# myChip register map
Vendor: ARM Ltd.; Series: ARMCM3; File version: 1.2
CPU: CM3 r2p1, little endian, no MPU, no FPU, 3 interrupt priority bits
Registers are 32-bit, read-write, reset 0x0 unless marked. A register's access mark holds for its fields unless they carry their own. Offsets are from the block's base; [hi:lo] are bit positions.

## WWDG
Base 0x4000D000
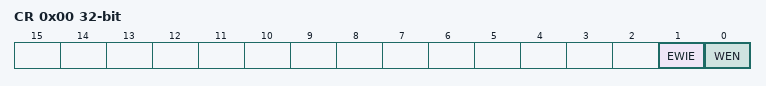
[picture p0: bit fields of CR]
0x00 CR — WWDG Control Register
  [1] EWIE — WWDG提前唤醒中断使能位（WWDG Early Wakeup Interrupt Enable）
  [0] WEN — WWDG使能位（WWDG Enable）
0x04 WVR — WWDG Window Register
  [15:0] WV — WWDG窗口比较值（WWDG Window Value）
0x08 CVR — WWDG Counter Register
  [15:0] CV — WWDG递减计数值（WWDG Counter Value）
0x0C PSCR — WWDG Prescaler Register
  [15:0] PSC — WWDG预分频器（WWDG Prescaler divider）
0x10 ISR — WWDG Status Register
  [0] EWIF — WWDG提前唤醒中断标志位（WWDG Early Wakeup Interrupt Flag）

## PDM0
Base 0x40017000
Same registers: PDM1 0x40017100, PDM2 0x40017200, PDM3 0x40017300
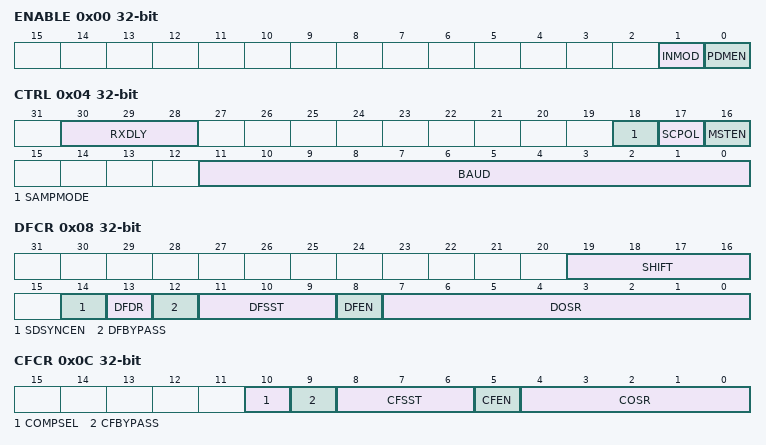
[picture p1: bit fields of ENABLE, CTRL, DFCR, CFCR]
0x00 ENABLE — PDM Enable Register
  [1] INMOD — PDM 输入模式位（PDM Input Mode）
  [0] PDMEN — PDM使能位（PDM Enable）
0x04 CTRL — PDM Control Register
  [30:28] RXDLY — SPI接收采样延迟（SPI RX Delay）
  [18] SAMPMODE — 从机时采样模式选择（Slave Sample Mode）
  [17] SCPOL — 串行时钟极性（Serial Clock Polarity）
  [16] MSTEN — PDM主机使能位（PDM Master Enable）
  [11:0] BAUD — 波特率配置（Baud Rate Configuration）
0x08 DFCR — PDM Main Filter Control Register
  [19:16] SHIFT — 移位控制选择位（Shift Control Select）
  [14] SDSYNCEN — SDSYNC信号使能位（SDSYNC Enable）
  [13] DFDR — 主滤波器输出数据位宽选择（Data Filter Output Data Length）
  [12] DFBYPASS — 主滤波器bypass使能（Data Filter Bypass Enable）
  [11:9] DFSST — 主滤波器类型（Data Filter Structure）
  [8] DFEN — 主滤波器使能位（Data Filter Enable）
  [7:0] DOSR — 主滤波器过采样值（Data filter Oversampling ratio）
0x0C CFCR — PDM Compare Filter Control Register
  [10] COMPSEL — 比较滤波器输出选择（Comparator Filter Output Select）
  [9] CFBYPASS — 比较滤波器bypass使能位（Comparator Filter Bypass Enable）
  [8:6] CFSST — 比较滤波器类型（Comparator Filter Structure）
  [5] CFEN — 比较滤波器使能位（Comparator Filter Enable）
  [4:0] COSR — 比较滤波器过采样值（Comparator filter Oversampling ratio）
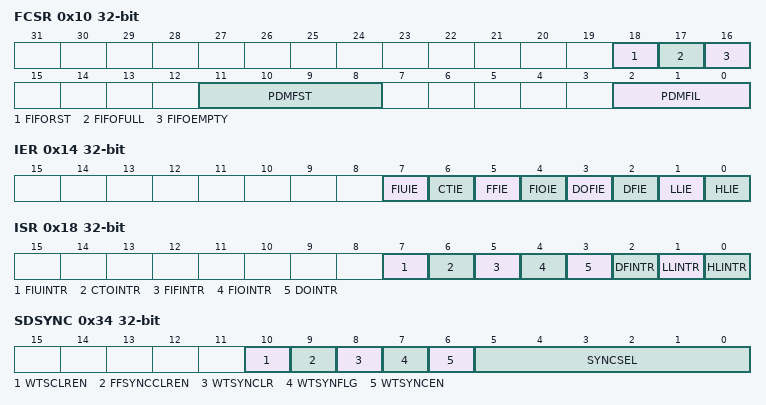
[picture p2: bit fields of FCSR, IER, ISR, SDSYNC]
0x10 FCSR — PDM FIFO Control Register
  [18] FIFORST — FIFO复位（FIFO Reset）
  [17] FIFOFULL ro — FIFO满标志（FIFO Full Flag）
  [16] FIFOEMPTY ro — FIFO空标志（FIFO Empty Flag）
  [11:8] PDMFST ro — FIFO状态（FIFO Status）
  [2:0] PDMFIL — FIFO满中断阈值选择。
0x14 IER — PDM Interrupt Enable Register
  [7] FIUIE — FIUINTR中断使能（FIUINTR Interrupt Enable）
  [6] CTIE — CTOINTR中断使能（CTOINTR Interrupt Enable）
  [5] FFIE — FIFINTR中断使能（FIFINTR Interrupt Enable）
  [4] FIOIE — FIOINTR中断使能（FIOINTR Interrupt Enable）
  [3] DOFIE — DOINTR中断使能（DOINTR Interrupt Enable）
  [2] DFIE — DFINTR中断使能（DFINTR Interrupt Enable）
  [1] LLIE — LLINTR中断使能（LLINTR Interrupt Enable）
  [0] HLIE — HLINTR中断使能（HLINTR Interrupt Enable）
0x18 ISR — PDM Interrupt State Register
  [7] FIUINTR — FIFO下溢中断（FIFO Underflow Interrupt）
  [6] CTOINTR — 时钟超时中断（Clock Timeout Interrupt）
  [5] FIFINTR ro — FIFO满中断（FIFO Full Interrupt）
  [4] FIOINTR — FIFO上溢中断（FIFO Overflow Interrupt）
  [3] DOINTR — 数据溢出中断（Data Overflow Interrupt）
  [2] DFINTR — 数据完成中断（Data Finish Interrupt）
  [1] LLINTR — 低阈值中断（Low Level Interrupt）
  [0] HLINTR — 高阈值中断（High Level Interrupt）
0x1C DDAT — PDM Main Filter Result Register
  [23:0] DDAT ro — 主滤波器数据寄存器（Data Filter Data Register）
0x20 CDAT — PDM Compare Filter Result Register
  [15:0] CDAT ro — 比较滤波器数据寄存器（Comparator Filter Data Register）
0x24 FDAT — PDM FIFO Result Register
  [23:0] FDAT ro — FIFO数据寄存器（FIFO Data Register）
0x28 CMPH — PDM High-Level Compare Register
  [15:0] HLT — 比较滤波器的高阈值（Comparator High-Level Data）
0x2C CMPL — PDM Low-Level Compare Register
  [15:0] LLT — 比较滤波器的低阈值（Comparator Low-Level Data）
0x30 CLKTO — PDM Clock Timeout Register
  [17:0] CLKTOT — PDM时钟超时寄存器（Clock Timeout Register）
0x34 SDSYNC — PDM Synchronization Control Register
  [10] WTSCLREN — WTSYNFLG清除使能位（WTSYNFLG Clear Enable）
  [9] FFSYNCCLREN — SDSYNC信号复位FIFO使能位（FIFO Reset By SDSYNC）
  [8] WTSYNCLR — WTSYNFLG清除位（WTSYNFLG Clear Enable）
  [7] WTSYNFLG ro — 收到SDSYNC标志（Receive SDSYNC Flag）
  [6] WTSYNCEN — FIFO在WTSYNFLG标志下的表现（The performance of FIFO under the WTSYNFLG）
  [5:0] SYNCSEL — SDSYNC选择（SDSYNC Select）
0x38 IDAT — PDM Input Data Register
  [15:0] IDAT — 输入数据寄存器（Input Data Register）
